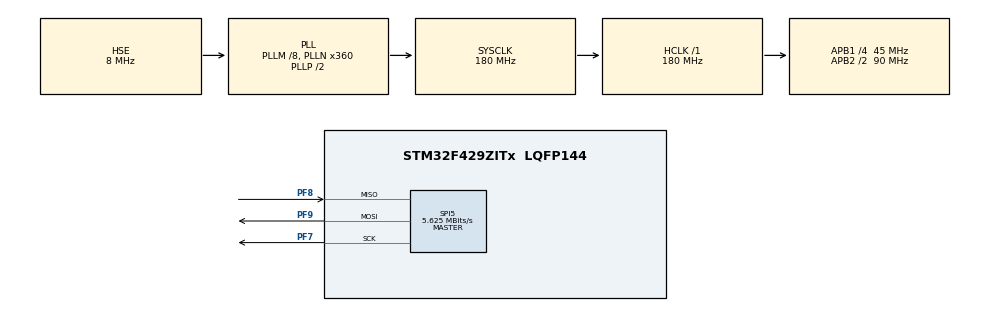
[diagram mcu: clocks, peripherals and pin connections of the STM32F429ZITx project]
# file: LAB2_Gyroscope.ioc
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Mcu.Family=STM32F4
Mcu.Name=STM32F429ZITx
Mcu.Package=LQFP144
NVIC.PriorityGroup=NVIC_PRIORITYGROUP_4
PF7.Mode=Full_Duplex_Master
PF7.Signal=SPI5_SCK
PF8.Mode=Full_Duplex_Master
PF8.Signal=SPI5_MISO
PF9.Mode=Full_Duplex_Master
PF9.Signal=SPI5_MOSI
PH0/OSC_IN.Mode=HSE-External-Oscillator
PH0/OSC_IN.Signal=RCC_OSC_IN
PH1/OSC_OUT.Mode=HSE-External-Oscillator
PH1/OSC_OUT.Signal=RCC_OSC_OUT
ProjectManager.HeapSize=0x200
ProjectManager.StackSize=0x400
ProjectManager.TargetToolchain=STM32CubeIDE
RCC.48MHZClocksFreq_Value=90000000
RCC.AHBFreq_Value=180000000
RCC.APB1CLKDivider=RCC_HCLK_DIV4
RCC.APB1Freq_Value=45000000
RCC.APB1TimFreq_Value=90000000
RCC.APB2CLKDivider=RCC_HCLK_DIV2
RCC.APB2Freq_Value=90000000
RCC.APB2TimFreq_Value=180000000
RCC.CortexFreq_Value=180000000
RCC.HCLKFreq_Value=180000000
RCC.HSE_VALUE=8000000
RCC.HSI_VALUE=16000000
RCC.LSE_VALUE=32768
RCC.PLLM=8
RCC.PLLN=360
RCC.PLLSourceVirtual=RCC_PLLSOURCE_HSE
RCC.SYSCLKFreq_VALUE=180000000
RCC.SYSCLKSource=RCC_SYSCLKSOURCE_PLLCLK
RCC.VCOOutputFreq_Value=360000000
SPI5.BaudRatePrescaler=SPI_BAUDRATEPRESCALER_16
SPI5.CalculateBaudRate=5.625 MBits/s
SPI5.Direction=SPI_DIRECTION_2LINES
SPI5.Mode=SPI_MODE_MASTER
SPI5.VirtualType=VM_MASTER
board=custom

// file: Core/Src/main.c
/* USER CODE BEGIN Header */
/**
  ******************************************************************************
  * @file           : main.c
  * @brief          : Main program body
  ******************************************************************************
  * @attention
  *
  * Copyright (c) 2022 STMicroelectronics.
  * All rights reserved.
  *
  * This software is licensed under terms that can be found in the LICENSE file
  * in the root directory of this software component.
  * If no LICENSE file comes with this software, it is provided AS-IS.
  *
  ******************************************************************************
  */
/* USER CODE END Header */
#include "main.h"

/* USER CODE BEGIN Includes */
#include "stm32f429i_discovery_lcd.h"
#include "stm32f429i_discovery_gyroscope.h"

/* USER CODE END Includes */

SPI_HandleTypeDef hspi5;

/* USER CODE BEGIN PV */
volatile uint32_t value;
/* USER CODE END PV */

void SystemClock_Config(void);
static void MX_GPIO_Init(void);
static void MX_SPI5_Init(void);

int main(void)
{
	float pfData[5];
	char buffer[100];

  /* MCU Configuration--------------------------------------------------------*/

  /* Reset of all peripherals, Initializes the Flash interface and the Systick. */
  HAL_Init();
  BSP_GYRO_Init();

  /* Configure the system clock */
  SystemClock_Config();

  /* Initialize all configured peripherals */
  MX_GPIO_Init();
  MX_SPI5_Init();
  /* USER CODE BEGIN 2 */
  BSP_LCD_Init();//init LCD
  //set the layer buffer address into SDRAM
  BSP_LCD_LayerDefaultInit(1, SDRAM_DEVICE_ADDR);
  BSP_LCD_SelectLayer(1);//select on which layer we write
  BSP_LCD_DisplayOn();//turn on LCD
  BSP_LCD_Clear(LCD_COLOR_BLUE);//clear the LCD on blue color
  BSP_LCD_SetBackColor(LCD_COLOR_BLUE);//set text background color
  BSP_LCD_SetTextColor(LCD_COLOR_WHITE);//set text color
  //write text

  /* USER CODE END 2 */

  /* Infinite loop */
  /* USER CODE BEGIN WHILE */
  while (1)
  {
	 BSP_GYRO_GetXYZ(pfData);
    /* USER CODE END WHILE */
	 sprintf(buffer, "X %4f", pfData[0]);
	 BSP_LCD_DisplayStringAtLine(2, buffer);
	 sprintf(buffer, "Y %4f", pfData[1]);
	 BSP_LCD_DisplayStringAtLine(3, buffer);
	 sprintf(buffer, "Z %4f", pfData[2]);
	 BSP_LCD_DisplayStringAtLine(4, buffer);
	 HAL_Delay(1000);
  }
}

void SystemClock_Config(void)
{
  RCC_OscInitTypeDef RCC_OscInitStruct = {0};
  RCC_ClkInitTypeDef RCC_ClkInitStruct = {0};

  /** Configure the main internal regulator output voltage
  */
  __HAL_RCC_PWR_CLK_ENABLE();
  __HAL_PWR_VOLTAGESCALING_CONFIG(PWR_REGULATOR_VOLTAGE_SCALE1);

  /** Initializes the RCC Oscillators according to the specified parameters
  * in the RCC_OscInitTypeDef structure.
  */
  RCC_OscInitStruct.OscillatorType = RCC_OSCILLATORTYPE_HSE;
  RCC_OscInitStruct.HSEState = RCC_HSE_ON;
  RCC_OscInitStruct.PLL.PLLState = RCC_PLL_ON;
  RCC_OscInitStruct.PLL.PLLSource = RCC_PLLSOURCE_HSE;
  RCC_OscInitStruct.PLL.PLLM = 8;
  RCC_OscInitStruct.PLL.PLLN = 360;
  RCC_OscInitStruct.PLL.PLLP = RCC_PLLP_DIV2;
  RCC_OscInitStruct.PLL.PLLQ = 4;
  if (HAL_RCC_OscConfig(&RCC_OscInitStruct) != HAL_OK)
  {
    Error_Handler();
  }

  /** Activate the Over-Drive mode
  */
  if (HAL_PWREx_EnableOverDrive() != HAL_OK)
  {
    Error_Handler();
  }

  /** Initializes the CPU, AHB and APB buses clocks
  */
  RCC_ClkInitStruct.ClockType = RCC_CLOCKTYPE_HCLK|RCC_CLOCKTYPE_SYSCLK
                              |RCC_CLOCKTYPE_PCLK1|RCC_CLOCKTYPE_PCLK2;
  RCC_ClkInitStruct.SYSCLKSource = RCC_SYSCLKSOURCE_PLLCLK;
  RCC_ClkInitStruct.AHBCLKDivider = RCC_SYSCLK_DIV1;
  RCC_ClkInitStruct.APB1CLKDivider = RCC_HCLK_DIV4;
  RCC_ClkInitStruct.APB2CLKDivider = RCC_HCLK_DIV2;

  if (HAL_RCC_ClockConfig(&RCC_ClkInitStruct, FLASH_LATENCY_5) != HAL_OK)
  {
    Error_Handler();
  }
}

static void MX_SPI5_Init(void)
{

  /* SPI5 parameter configuration*/
  hspi5.Instance = SPI5;
  hspi5.Init.Mode = SPI_MODE_MASTER;
  hspi5.Init.Direction = SPI_DIRECTION_2LINES;
  hspi5.Init.DataSize = SPI_DATASIZE_8BIT;
  hspi5.Init.CLKPolarity = SPI_POLARITY_LOW;
  hspi5.Init.CLKPhase = SPI_PHASE_1EDGE;
  hspi5.Init.NSS = SPI_NSS_SOFT;
  hspi5.Init.BaudRatePrescaler = SPI_BAUDRATEPRESCALER_16;
  hspi5.Init.FirstBit = SPI_FIRSTBIT_MSB;
  hspi5.Init.TIMode = SPI_TIMODE_DISABLE;
  hspi5.Init.CRCCalculation = SPI_CRCCALCULATION_DISABLE;
  hspi5.Init.CRCPolynomial = 10;
  if (HAL_SPI_Init(&hspi5) != HAL_OK)
  {
    Error_Handler();
  }

}

static void MX_GPIO_Init(void)
{

  /* GPIO Ports Clock Enable */
  __HAL_RCC_GPIOF_CLK_ENABLE();
  __HAL_RCC_GPIOH_CLK_ENABLE();

}

void Error_Handler(void)
{
  __disable_irq();
  while (1)
  {
  }
}
